VERSION "created by canmatrix"

NS_ :

BS_:

BU_: User ADM_PC_LL25 ADM_PC_BC25 ADM_PC_BP25 ADM_PC_BI25

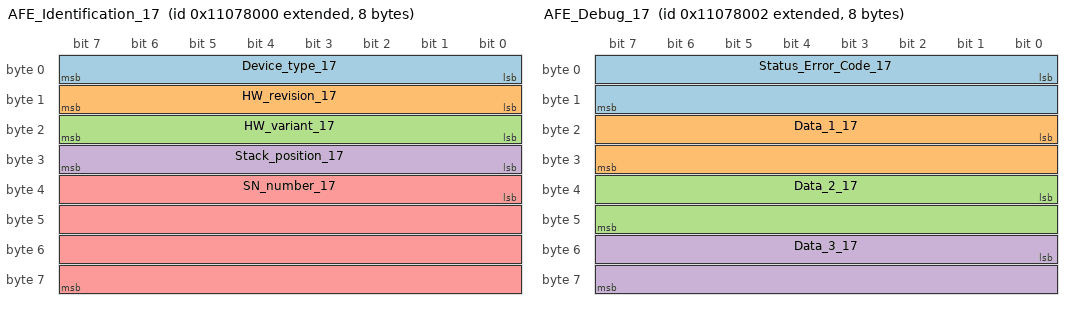
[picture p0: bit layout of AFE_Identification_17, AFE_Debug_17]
BO_ 2433187840 AFE_Identification_17: 8 ADM_PC_BP25
 SG_ Device_type_17 : 0|8@1+ (1,0) [0|255] "" Vector__XXX
 SG_ HW_revision_17 : 8|8@1+ (1,0) [0|255] "" Vector__XXX
 SG_ HW_variant_17 : 16|8@1+ (1,0) [0|255] "" Vector__XXX
 SG_ Stack_position_17 : 24|8@1+ (1,0) [0|255] "" Vector__XXX
 SG_ SN_number_17 : 32|32@1+ (1,0) [0|4294967295] "" Vector__XXX

BO_ 2433187841 AFE_FwInfo_17: 8 ADM_PC_BP25
 SG_ FW_info_mux_17 M : 56|8@1+ (1,0) [0|255] "" Vector__XXX
 SG_ FW_revision_0_17 m0 : 0|8@1+ (1,0) [0|255] "" Vector__XXX
 SG_ FW_revision_1_17 m0 : 8|8@1+ (1,0) [0|255] "" Vector__XXX
 SG_ FW_revision_2_17 m0 : 16|8@1+ (1,0) [0|255] "" Vector__XXX
 SG_ FW_revision_3_17 m0 : 24|8@1+ (1,0) [0|255] "" Vector__XXX
 SG_ FW_revision_4_17 m0 : 32|8@1+ (1,0) [0|255] "" Vector__XXX
 SG_ FW_revision_5_17 m0 : 40|8@1+ (1,0) [0|255] "" Vector__XXX
 SG_ FW_revision_6_17 m0 : 48|8@1+ (1,0) [0|255] "" Vector__XXX
 SG_ FW_revision_7_17 m1 : 0|8@1+ (1,0) [0|255] "" Vector__XXX
 SG_ FW_revision_8_17 m1 : 8|8@1+ (1,0) [0|255] "" Vector__XXX
 SG_ FW_revision_9_17 m1 : 16|8@1+ (1,0) [0|255] "" Vector__XXX
 SG_ FW_revision_10_17 m1 : 24|8@1+ (1,0) [0|255] "" Vector__XXX
 SG_ FW_revision_11_17 m1 : 32|8@1+ (1,0) [0|255] "" Vector__XXX
 SG_ FW_revision_12_17 m1 : 40|8@1+ (1,0) [0|255] "" Vector__XXX
 SG_ FW_revision_13_17 m1 : 48|8@1+ (1,0) [0|255] "" Vector__XXX
 SG_ FW_datecode_0_17 m2 : 0|8@1+ (1,0) [0|255] "" Vector__XXX
 SG_ FW_datecode_1_17 m2 : 8|8@1+ (1,0) [0|255] "" Vector__XXX
 SG_ FW_datecode_2_17 m2 : 16|8@1+ (1,0) [0|255] "" Vector__XXX
 SG_ FW_datecode_3_17 m2 : 24|8@1+ (1,0) [0|255] "" Vector__XXX
 SG_ FW_datecode_4_17 m2 : 32|8@1+ (1,0) [0|255] "" Vector__XXX
 SG_ FW_datecode_5_17 m2 : 40|8@1+ (1,0) [0|255] "" Vector__XXX
 SG_ FW_datecode_6_17 m2 : 48|8@1+ (1,0) [0|255] "" Vector__XXX
 SG_ FW_datecode_7_17 m3 : 0|8@1+ (1,0) [0|255] "" Vector__XXX
 SG_ FW_datecode_8_17 m3 : 8|8@1+ (1,0) [0|255] "" Vector__XXX
 SG_ FW_datecode_9_17 m3 : 16|8@1+ (1,0) [0|255] "" Vector__XXX
 SG_ FW_datecode_10_17 m3 : 24|8@1+ (1,0) [0|255] "" Vector__XXX
 SG_ FW_datecode_11_17 m3 : 32|8@1+ (1,0) [0|255] "" Vector__XXX
 SG_ FW_datecode_12_17 m3 : 40|8@1+ (1,0) [0|255] "" Vector__XXX
 SG_ FW_datecode_13_17 m3 : 48|8@1+ (1,0) [0|255] "" Vector__XXX

BO_ 2433187853 _AFE_Boot_FwInfo_17: 8 ADM_PC_BP25
 SG_ Boot_FW_info_mux_17 M : 56|8@1+ (1,0) [0|255] "" Vector__XXX
 SG_ FW_revision_0_17 m0 : 0|8@1+ (1,0) [0|255] "" Vector__XXX
 SG_ FW_revision_1_17 m0 : 8|8@1+ (1,0) [0|255] "" Vector__XXX
 SG_ FW_revision_2_17 m0 : 16|8@1+ (1,0) [0|255] "" Vector__XXX
 SG_ FW_revision_3_17 m0 : 24|8@1+ (1,0) [0|255] "" Vector__XXX
 SG_ FW_revision_4_17 m0 : 32|8@1+ (1,0) [0|255] "" Vector__XXX
 SG_ FW_revision_5_17 m0 : 40|8@1+ (1,0) [0|255] "" Vector__XXX
 SG_ FW_revision_6_17 m0 : 48|8@1+ (1,0) [0|255] "" Vector__XXX
 SG_ FW_revision_7_17 m1 : 0|8@1+ (1,0) [0|255] "" Vector__XXX
 SG_ FW_revision_8_17 m1 : 8|8@1+ (1,0) [0|255] "" Vector__XXX
 SG_ FW_revision_9_17 m1 : 16|8@1+ (1,0) [0|255] "" Vector__XXX
 SG_ FW_revision_10_17 m1 : 24|8@1+ (1,0) [0|255] "" Vector__XXX
 SG_ FW_revision_11_17 m1 : 32|8@1+ (1,0) [0|255] "" Vector__XXX
 SG_ FW_revision_12_17 m1 : 40|8@1+ (1,0) [0|255] "" Vector__XXX
 SG_ FW_revision_13_17 m1 : 48|8@1+ (1,0) [0|255] "" Vector__XXX
 SG_ FW_datecode_0_17 m2 : 0|8@1+ (1,0) [0|255] "" Vector__XXX
 SG_ FW_datecode_1_17 m2 : 8|8@1+ (1,0) [0|255] "" Vector__XXX
 SG_ FW_datecode_2_17 m2 : 16|8@1+ (1,0) [0|255] "" Vector__XXX
 SG_ FW_datecode_3_17 m2 : 24|8@1+ (1,0) [0|255] "" Vector__XXX
 SG_ FW_datecode_4_17 m2 : 32|8@1+ (1,0) [0|255] "" Vector__XXX
 SG_ FW_datecode_5_17 m2 : 40|8@1+ (1,0) [0|255] "" Vector__XXX
 SG_ FW_datecode_6_17 m2 : 48|8@1+ (1,0) [0|255] "" Vector__XXX
 SG_ FW_datecode_7_17 m3 : 0|8@1+ (1,0) [0|255] "" Vector__XXX
 SG_ FW_datecode_8_17 m3 : 8|8@1+ (1,0) [0|255] "" Vector__XXX
 SG_ FW_datecode_9_17 m3 : 16|8@1+ (1,0) [0|255] "" Vector__XXX
 SG_ FW_datecode_10_17 m3 : 24|8@1+ (1,0) [0|255] "" Vector__XXX
 SG_ FW_datecode_11_17 m3 : 32|8@1+ (1,0) [0|255] "" Vector__XXX
 SG_ FW_datecode_12_17 m3 : 40|8@1+ (1,0) [0|255] "" Vector__XXX
 SG_ FW_datecode_13_17 m3 : 48|8@1+ (1,0) [0|255] "" Vector__XXX

BO_ 2433187842 AFE_Debug_17: 8 ADM_PC_BP25
 SG_ Status_Error_Code_17 : 0|16@1+ (1,0) [0|65535] "" Vector__XXX
 SG_ Data_1_17 : 16|16@1+ (1,0) [0|65535] "" Vector__XXX
 SG_ Data_2_17 : 32|16@1+ (1,0) [0|65535] "" Vector__XXX
 SG_ Data_3_17 : 48|16@1+ (1,0) [0|65535] "" Vector__XXX

BO_ 2433187847 AFE_Status_17: 8 ADM_PC_BP25
 SG_ Running_17 : 0|1@1+ (1,0) [0|1] "" Vector__XXX
 SG_ PWM_17 : 1|1@1+ (1,0) [0|1] "" Vector__XXX
 SG_ Current_dc_loop_mode_17 : 2|1@1+ (1,0) [0|1] "" Vector__XXX
 SG_ Current_ac_loop_mode_17 : 3|1@1+ (1,0) [0|1] "" Vector__XXX
 SG_ Buck_17 : 5|1@1+ (1,0) [0|1] "" Vector__XXX
 SG_ Boost_17 : 6|1@1+ (1,0) [0|1] "" Vector__XXX
 SG_ Precharge_dc_buck_mode_17 : 7|1@1+ (1,0) [0|1] "" Vector__XXX
 SG_ Precharge_dc_boost_mode_17 : 8|1@1+ (1,0) [0|1] "" Vector__XXX
 SG_ Rectifier_3ph_17 : 9|1@1+ (1,0) [0|1] "" Vector__XXX
 SG_ Stack_mode_17 : 10|1@1+ (1,0) [0|1] "" Vector__XXX
 SG_ Master_17 : 11|1@1+ (1,0) [0|1] "" Vector__XXX
 SG_ Slave_17 : 12|1@1+ (1,0) [0|1] "" Vector__XXX
 SG_ Inverter_1ph_17 : 13|1@1+ (1,0) [0|1] "" Vector__XXX
 SG_ Boost_Neutral_17 : 14|1@1+ (1,0) [0|1] "" Vector__XXX
 SG_ Rectifier_1ph_17 : 15|1@1+ (1,0) [0|1] "" Vector__XXX
 SG_ Inverter_3ph_17 : 16|1@1+ (1,0) [0|1] "" Vector__XXX
 SG_ Ready_17 : 17|1@1+ (1,0) [0|1] "" Vector__XXX
 SG_ Inverter_1ph_Sync_17 : 18|1@1+ (1,0) [0|1] "" Vector__XXX
 SG_ Neutral_17 : 19|1@1+ (1,0) [0|1] "" Vector__XXX
 SG_ Rectifier_1ph_Buck_17 : 20|1@1+ (1,0) [0|1] "" Vector__XXX
 SG_ Inverter_1ph_Boost_17 : 21|1@1+ (1,0) [0|1] "" Vector__XXX
 SG_ Rectifier_distributed_17 : 22|1@1+ (1,0) [0|1] "" Vector__XXX
 SG_ MPPT_buck_17 : 23|1@1+ (1,0) [0|1] "" Vector__XXX
 SG_ MPPT_boost_17 : 24|1@1+ (1,0) [0|1] "" Vector__XXX
 SG_ Buck_2p_float_17 : 25|1@1+ (1,0) [0|1] "" Vector__XXX
 SG_ Inverter_1ph_Distributed_17 : 26|1@1+ (1,0) [0|1] "" Vector__XXX

BO_ 2433187846 AFE_Faults_17: 3 ADM_PC_BP25
 SG_ Protection_trip_internal_17 : 0|1@1+ (1,0) [0|1] "" Vector__XXX
 SG_ Protection_trip_external_17 : 1|1@1+ (1,0) [0|1] "" Vector__XXX
 SG_ Phase_U_overcurrent_17 : 2|1@1+ (1,0) [0|1] "" Vector__XXX
 SG_ Phase_U_overvoltage_17 : 3|1@1+ (1,0) [0|1] "" Vector__XXX
 SG_ Phase_U_undervoltage_17 : 4|1@1+ (1,0) [0|1] "" Vector__XXX
 SG_ Phase_V_overvoltage_17 : 5|1@1+ (1,0) [0|1] "" Vector__XXX
 SG_ Phase_V_undervoltage_17 : 6|1@1+ (1,0) [0|1] "" Vector__XXX
 SG_ Phase_V_overcurrent_17 : 7|1@1+ (1,0) [0|1] "" Vector__XXX
 SG_ Phase_W_overvoltage_17 : 8|1@1+ (1,0) [0|1] "" Vector__XXX
 SG_ Phase_W_undervoltage_17 : 9|1@1+ (1,0) [0|1] "" Vector__XXX
 SG_ Phase_W_overcurrent_17 : 10|1@1+ (1,0) [0|1] "" Vector__XXX
 SG_ DC_undervoltage_17 : 11|1@1+ (1,0) [0|1] "" Vector__XXX
 SG_ DC_overvoltage_17 : 12|1@1+ (1,0) [0|1] "" Vector__XXX
 SG_ MOSFET_overtemperature_17 : 13|1@1+ (1,0) [0|1] "" Vector__XXX
 SG_ Inductor_overtemperature_17 : 14|1@1+ (1,0) [0|1] "" Vector__XXX
 SG_ Keep_Alive_not_served_17 : 15|1@1+ (1,0) [0|1] "" Vector__XXX
 SG_ PLL_not_locked_17 : 16|1@1+ (1,0) [0|1] "" Vector__XXX
 SG_ NFO_17 : 20|1@1+ (1,0) [0|1] "" Vector__XXX
 SG_ Measurement_system_failure_17 : 21|1@1+ (1,0) [0|1] "" Vector__XXX
 SG_ EEPROM_failure_17 : 22|1@1+ (1,0) [0|1] "" Vector__XXX
 SG_ System_17 : 23|1@1+ (1,0) [0|1] "" Vector__XXX

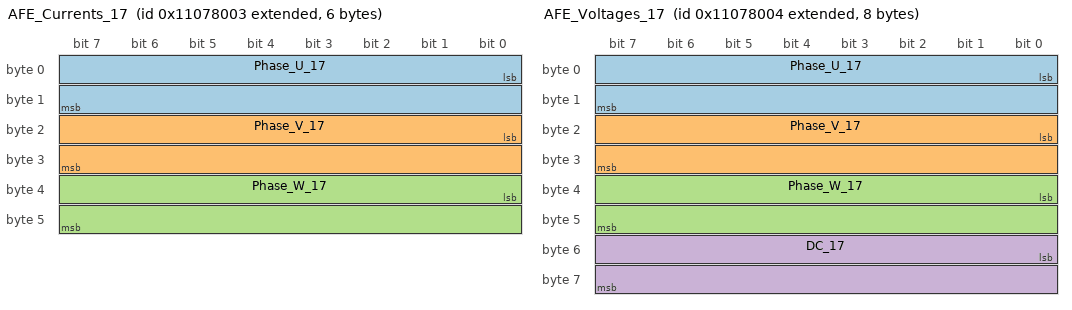
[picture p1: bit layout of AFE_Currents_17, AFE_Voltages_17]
BO_ 2433187843 AFE_Currents_17: 6 ADM_PC_BP25
 SG_ Phase_U_17 : 0|16@1- (0.01,0) [-327.68|327.67] "A" Vector__XXX
 SG_ Phase_V_17 : 16|16@1- (0.01,0) [-327.68|327.67] "A" Vector__XXX
 SG_ Phase_W_17 : 32|16@1- (0.01,0) [-327.68|327.67] "A" Vector__XXX

BO_ 2433187856 AFE_DC_Bus_current_17: 2 ADM_PC_BP25
 SG_ Bus_current_17 : 0|16@1- (0.01,0) [-327.68|327.67] "A" Vector__XXX

BO_ 2433187854 _AFE_Broadcast_17: 8 ADM_PC_BP25
 SG_ Diagnostics_Index_17 M : 56|8@1+ (1,0) [0|255] "" Vector__XXX
 SG_ Phase_U_17 m1 : 8|16@1- (0.01,0) [-327.68|327.67] "A" ADM_PC_BP25
 SG_ Phase_V_17 m1 : 24|16@1- (0.01,0) [-327.68|327.67] "A" ADM_PC_BP25
 SG_ Phase_W_17 m1 : 40|16@1- (0.01,0) [-327.68|327.67] "A" ADM_PC_BP25
 SG_ Stack_position_17 : 0|5@1+ (1,0) [0|31] "" ADM_PC_BP25
 SG_ Group_ID_17 : 5|3@1+ (1,0) [0|7] "" ADM_PC_BP25

BO_ 2433187844 AFE_Voltages_17: 8 ADM_PC_BP25
 SG_ Phase_U_17 : 0|16@1- (0.1,0) [-3276.8|3276.7] "V" Vector__XXX
 SG_ Phase_V_17 : 16|16@1- (0.1,0) [-3276.8|3276.7] "V" Vector__XXX
 SG_ Phase_W_17 : 32|16@1- (0.1,0) [-3276.8|3276.7] "V" Vector__XXX
 SG_ DC_17 : 48|16@1- (0.1,0) [-3276.8|3276.7] "V" Vector__XXX

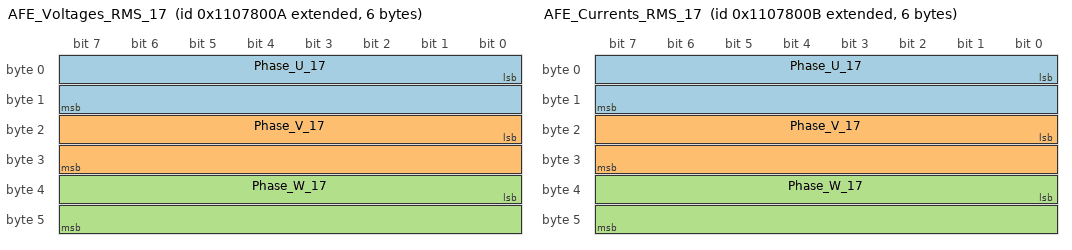
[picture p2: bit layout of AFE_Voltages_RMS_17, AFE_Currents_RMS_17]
BO_ 2433187850 AFE_Voltages_RMS_17: 6 ADM_PC_BP25
 SG_ Phase_U_17 : 0|16@1+ (0.1,0) [0|6553.5] "V" Vector__XXX
 SG_ Phase_V_17 : 16|16@1+ (0.1,0) [0|6553.5] "V" Vector__XXX
 SG_ Phase_W_17 : 32|16@1+ (0.1,0) [0|6553.5] "V" Vector__XXX

BO_ 2433187851 AFE_Currents_RMS_17: 6 ADM_PC_BP25
 SG_ Phase_U_17 : 0|16@1+ (0.01,0) [0.00|655.35] "A" Vector__XXX
 SG_ Phase_V_17 : 16|16@1+ (0.01,0) [0.00|655.35] "A" Vector__XXX
 SG_ Phase_W_17 : 32|16@1+ (0.01,0) [0.00|655.35] "A" Vector__XXX

BO_ 2433187852 AFE_Mains_17: 4 ADM_PC_BP25
 SG_ Frequency_17 : 0|16@1+ (0.01,0) [0.00|655.35] "Hz" Vector__XXX
 SG_ Phase_17 : 16|16@1- (0.1,0) [-3276.8|3276.7] "Deg." Vector__XXX

BO_ 2433187845 AFE_Temperatures_17: 4 ADM_PC_BP25
 SG_ Temp_Bridge_17 : 0|16@1- (0.01,0) [-327.68|327.67] "°C" Vector__XXX
 SG_ Temp_Inductors_17 : 16|16@1- (0.01,0) [-327.68|327.67] "°C" Vector__XXX

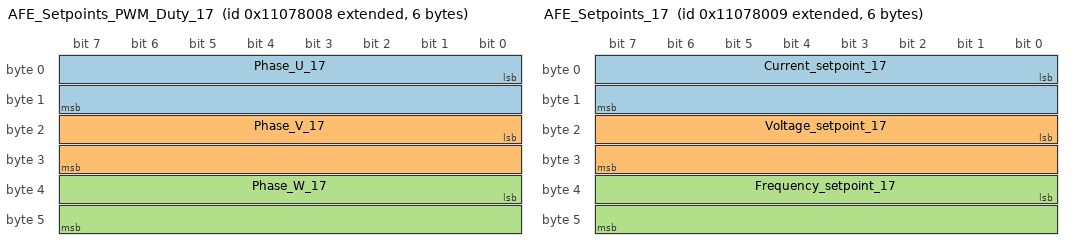
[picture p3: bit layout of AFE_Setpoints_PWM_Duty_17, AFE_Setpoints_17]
BO_ 2433187848 AFE_Setpoints_PWM_Duty_17: 6 ADM_PC_BP25
 SG_ Phase_U_17 : 0|16@1+ (0.001525902,0) [0E-009|99.999987570] "%" Vector__XXX
 SG_ Phase_V_17 : 16|16@1+ (0.001525902,0) [0E-009|99.999987570] "%" Vector__XXX
 SG_ Phase_W_17 : 32|16@1+ (0.001525902,0) [0E-009|99.999987570] "%" Vector__XXX

BO_ 2433187849 AFE_Setpoints_17: 6 ADM_PC_BP25
 SG_ Current_setpoint_17 : 0|16@1- (0.01,0) [-327.68|327.67] "A" Vector__XXX
 SG_ Voltage_setpoint_17 : 16|16@1+ (0.1,0) [0|6553.5] "V" Vector__XXX
 SG_ Frequency_setpoint_17 : 32|16@1+ (0.01,0) [0.00|655.35] "Hz" Vector__XXX

BO_ 2433155168 AFE_Keep_Alive_17: 1 User
 SG_ Keep_Alive_Enable_17 : 0|1@1+ (1,0) [0|1] "" ADM_PC_BP25

BO_ 2433155136 AFE_Mode_Control_17: 8 User
 SG_ Converter_ON_17 : 0|1@1+ (1,0) [0|1] "" ADM_PC_BP25
 SG_ PWM_ON_17 : 1|1@1+ (1,0) [0|1] "" ADM_PC_BP25
 SG_ DC_Current_feedback_ON_17 : 2|1@1+ (1,0) [0|1] "" ADM_PC_BP25
 SG_ AC_Current_feedback_ON_17 : 3|1@1+ (1,0) [0|1] "" ADM_PC_BP25
 SG_ Buck_ON_17 : 5|1@1+ (1,0) [0|1] "" ADM_PC_BP25
 SG_ Boost_ON_17 : 6|1@1+ (1,0) [0|1] "" ADM_PC_BP25
 SG_ Rectifier_3ph_ON_17 : 9|1@1+ (1,0) [0|1] "" ADM_PC_BP25
 SG_ Inverter_1ph_ON_17 : 10|1@1+ (1,0) [0|1] "" ADM_PC_BP25
 SG_ Rectifier_1ph_ON_17 : 11|1@1+ (1,0) [0|1] "" ADM_PC_BP25
 SG_ Boost_Neutral_ON_17 : 12|1@1+ (1,0) [0|1] "" ADM_PC_BP25
 SG_ Inverter_3ph_ON_17 : 13|1@1+ (1,0) [0|1] "" ADM_PC_BP25
 SG_ Inverter_1ph_Sync_ON_17 : 14|1@1+ (1,0) [0|1] "" ADM_PC_BP25
 SG_ Neutral_ON_17 : 15|1@1+ (1,0) [0|1] "" ADM_PC_BP25
 SG_ Rectifier_1ph_Buck_ON_17 : 16|1@1+ (1,0) [0|1] "" ADM_PC_BP25
 SG_ Inverter_1ph_Boost_ON_17 : 17|1@1+ (1,0) [0|1] "" ADM_PC_BP25
 SG_ Rectifier_Distributed_ON_17 : 18|1@1+ (1,0) [0|1] "" ADM_PC_BP25
 SG_ MPPT_buck_ON_17 : 19|1@1+ (1,0) [0|1] "" ADM_PC_BP25
 SG_ MPPT_boost_ON_17 : 20|1@1+ (1,0) [0|1] "" ADM_PC_BP25
 SG_ Buck_2p_float_ON_17 : 21|1@1+ (1,0) [0|1] "" ADM_PC_BP25
 SG_ Inverter_1ph_Distributed_ON_17 : 22|1@1+ (1,0) [0|1] "" ADM_PC_BP25

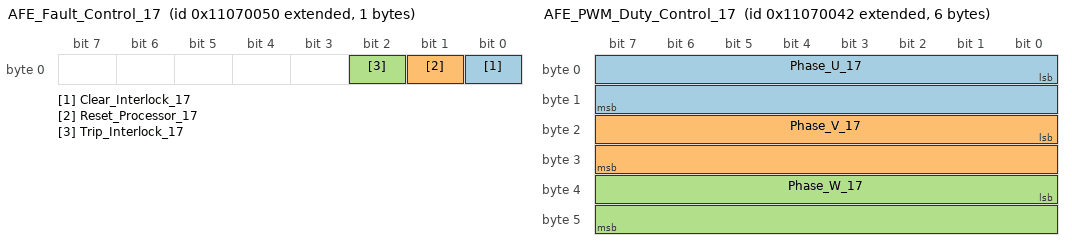
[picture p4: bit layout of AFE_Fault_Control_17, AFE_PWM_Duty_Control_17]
BO_ 2433155152 AFE_Fault_Control_17: 1 User
 SG_ Clear_Interlock_17 : 0|1@1+ (1,0) [0|1] "" ADM_PC_BP25
 SG_ Reset_Processor_17 : 1|1@1+ (1,0) [0|1] "" ADM_PC_BP25
 SG_ Trip_Interlock_17 : 2|1@1+ (1,0) [0|1] "" ADM_PC_BP25

BO_ 2433155137 AFE_Reactive_Current_Setpoint_Co: 2 User
 SG_ Reactive_current_setpoint_17 : 0|16@1- (0.01,0) [-150|150] "A" ADM_PC_BP25

BO_ 2433155138 AFE_PWM_Duty_Control_17: 6 User
 SG_ Phase_U_17 : 0|16@1+ (0.001525902,0) [0E-009|99.999987570] "%" ADM_PC_BP25
 SG_ Phase_V_17 : 16|16@1+ (0.001525902,0) [0E-009|99.999987570] "%" ADM_PC_BP25
 SG_ Phase_W_17 : 32|16@1+ (0.001525902,0) [0E-009|99.999987570] "%" ADM_PC_BP25

BO_ 2433155139 AFE_Current_Setpoint_Control_17: 2 User
 SG_ Current_setpoint_17 : 0|16@1- (0.01,0) [-150|150] "A" ADM_PC_BP25

BO_ 2433155140 AFE_Voltage_Setpoint_Control_17: 2 User
 SG_ Voltage_setpoint_17 : 0|16@1+ (0.1,0) [0|1500] "V" ADM_PC_BP25

BO_ 2433155144 AFE_Frequency_Setpoint_Control_1: 2 User
 SG_ Frequency_setpoint_17 : 0|16@1+ (0.01,0) [40|70] "Hz" ADM_PC_BP25

BO_ 2433155145 AFE_Phase_Setpoint_Control_17: 2 User
 SG_ Phase_setpoint_17 : 0|16@1+ (1,0) [0|360] "deg" ADM_PC_BP25

BO_ 2433155184 AFE_Rectifier_Setpoint_Control_1: 8 User
 SG_ Voltage_setpoint_2_17 : 0|16@1+ (0.1,0) [0|1500] "V" ADM_PC_BP25
 SG_ Current_setpoint_2_17 : 16|16@1- (0.01,0) [-150|150] "A" ADM_PC_BP25

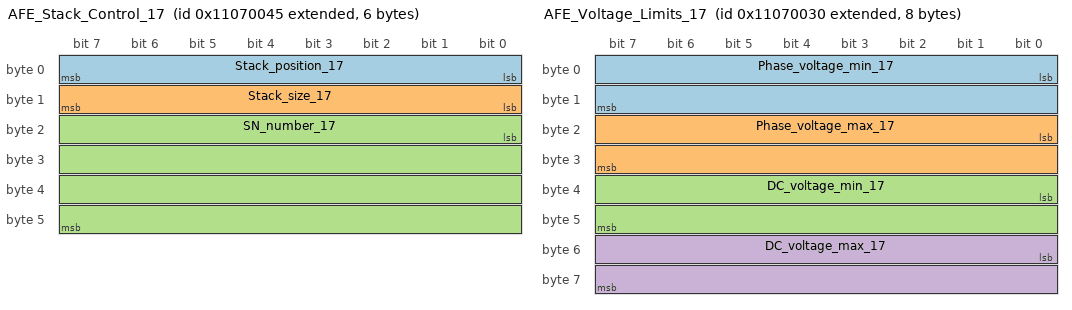
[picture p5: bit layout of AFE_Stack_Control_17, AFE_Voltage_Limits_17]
BO_ 2433155141 AFE_Stack_Control_17: 6 User
 SG_ Stack_position_17 : 0|8@1+ (1,0) [0|255] "" ADM_PC_BP25
 SG_ Stack_size_17 : 8|8@1+ (1,0) [0|255] "" ADM_PC_BP25
 SG_ SN_number_17 : 16|32@1+ (1,0) [0|4294967295] "" ADM_PC_BP25

BO_ 2433155120 AFE_Voltage_Limits_17: 8 User
 SG_ Phase_voltage_min_17 : 0|16@1- (0.1,0) [0|3276.7] "V" ADM_PC_BP25
 SG_ Phase_voltage_max_17 : 16|16@1- (0.1,0) [-3276.8|850] "V" ADM_PC_BP25
 SG_ DC_voltage_min_17 : 32|16@1- (0.1,0) [0|3276.7] "V" ADM_PC_BP25
 SG_ DC_voltage_max_17 : 48|16@1- (0.1,0) [-3276.8|850] "V" ADM_PC_BP25

BO_ 2433155121 AFE_Current_Limits_17: 4 User
 SG_ Phase_current_min_17 : 0|16@1- (0.01,0) [-60|60] "A" ADM_PC_BP25
 SG_ Phase_current_max_17 : 16|16@1- (0.01,0) [-60|60] "A" ADM_PC_BP25

BO_ 2433155148 AFE_Group_Control_17: 1 User
 SG_ Group_ID_17 : 0|8@1+ (1,0) [0|255] "" ADM_PC_BP25

BO_ 2433187855 AFE_Group_Info_17: 1 ADM_PC_BP25
 SG_ Group_ID_17 : 0|8@1+ (1,0) [0|255] "" Vector__XXX

BO_ 2433155169 AFE_System_Flags_Control_17: 8 User
 SG_ Factory_mode_17 : 0|1@1+ (1,0) [0|1] "" ADM_PC_BP25
 SG_ Silent_CAN_mode_17 : 1|1@1+ (1,0) [0|1] "" ADM_PC_BP25

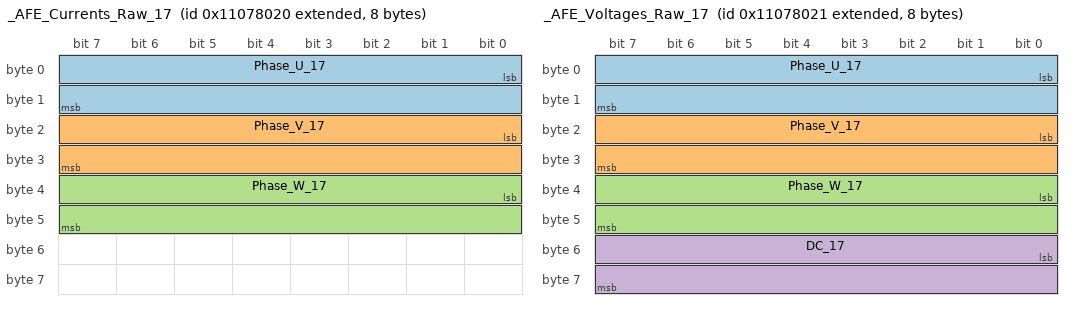
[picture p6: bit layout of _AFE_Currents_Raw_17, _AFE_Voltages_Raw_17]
BO_ 2433187872 _AFE_Currents_Raw_17: 8 ADM_PC_BP25
 SG_ Phase_U_17 : 0|16@1- (1,0) [-32768|32767] "" Vector__XXX
 SG_ Phase_V_17 : 16|16@1- (1,0) [-32768|32767] "" Vector__XXX
 SG_ Phase_W_17 : 32|16@1- (1,0) [-32768|32767] "" Vector__XXX

BO_ 2433187873 _AFE_Voltages_Raw_17: 8 ADM_PC_BP25
 SG_ Phase_U_17 : 0|16@1- (1,0) [-32768|32767] "" Vector__XXX
 SG_ Phase_V_17 : 16|16@1- (1,0) [-32768|32767] "" Vector__XXX
 SG_ Phase_W_17 : 32|16@1- (1,0) [-32768|32767] "" Vector__XXX
 SG_ DC_17 : 48|16@1- (1,0) [-32768|32767] "" Vector__XXX

BO_ 2433155146 _AFE_ADC_Calibration_Mode_17: 1 User
 SG_ Calibration_Index_17 M : 2|5@1+ (1,0) [0|31] "" Vector__XXX
 SG_ Current_U_17 m1 : 0|2@1+ (1,0) [0|3] "" ADM_PC_BP25
 SG_ Current_V_17 m2 : 0|2@1+ (1,0) [0|3] "" ADM_PC_BP25
 SG_ Current_W_17 m3 : 0|2@1+ (1,0) [0|3] "" ADM_PC_BP25
 SG_ Voltage_U_17 m4 : 0|2@1+ (1,0) [0|3] "" ADM_PC_BP25
 SG_ Voltage_V_17 m5 : 0|2@1+ (1,0) [0|3] "" ADM_PC_BP25
 SG_ Voltage_W_17 m6 : 0|2@1+ (1,0) [0|3] "" ADM_PC_BP25
 SG_ Voltage_DC_17 m7 : 0|2@1+ (1,0) [0|3] "" ADM_PC_BP25
 SG_ start_17 : 7|1@1+ (1,0) [0|1] "" ADM_PC_BP25

BO_ 2433155147 _AFE_ADC_Calibration_Setpoint_17: 3 User
 SG_ Calibration_Index_17 M : 16|5@1+ (1,0) [0|31] "" Vector__XXX
 SG_ Current_U_17 m1 : 0|16@1- (0.01,0) [-100|100] "A" ADM_PC_BP25
 SG_ Current_V_17 m2 : 0|16@1- (0.01,0) [-100|100] "A" ADM_PC_BP25
 SG_ Current_W_17 m3 : 0|16@1- (0.01,0) [-100|100] "A" ADM_PC_BP25
 SG_ Voltage_U_17 m4 : 0|16@1+ (0.1,0) [0|1500] "V" ADM_PC_BP25
 SG_ Voltage_V_17 m5 : 0|16@1+ (0.1,0) [0|1500] "V" ADM_PC_BP25
 SG_ Voltage_W_17 m6 : 0|16@1+ (0.1,0) [0|1500] "V" ADM_PC_BP25
 SG_ Voltage_DC_17 m7 : 0|16@1+ (0.1,0) [0|1500] "V" ADM_PC_BP25
 SG_ point_17 : 21|3@1+ (1,0) [0|7] "" ADM_PC_BP25

BO_ 2433155142 _AFE_Calibration_Offset_Update_1: 6 User
 SG_ Calibration_Index_17 M : 16|16@1+ (1,0) [0|65535] "" Vector__XXX
 SG_ Current_U_17 m0 : 0|16@1- (1,0) [-32768|32767] "ADC Counts" ADM_PC_BP25
 SG_ Current_V_17 m1 : 0|16@1- (1,0) [-32768|32767] "ADC Counts" ADM_PC_BP25
 SG_ Current_W_17 m2 : 0|16@1- (1,0) [-32768|32767] "ADC Counts" ADM_PC_BP25
 SG_ Voltage_U_17 m3 : 0|16@1- (1,0) [-32768|32767] "ADC Counts" ADM_PC_BP25
 SG_ Voltage_V_17 m4 : 0|16@1- (1,0) [-32768|32767] "ADC Counts" ADM_PC_BP25
 SG_ Voltage_W_17 m5 : 0|16@1- (1,0) [-32768|32767] "ADC Counts" ADM_PC_BP25
 SG_ Voltage_DC_17 m6 : 0|16@1- (1,0) [-32768|32767] "ADC Counts" ADM_PC_BP25
 SG_ CRC_17 : 32|16@1+ (1,0) [0|65535] "-" ADM_PC_BP25

BO_ 2433155143 _AFE_Calibration_Scale_Update_17: 6 User
 SG_ Calibration_Index_17 M : 16|16@1+ (1,0) [0|65535] "" Vector__XXX
 SG_ Current_U_17 m0 : 0|16@1- (0.0000152587890625,0) [-0.5000000000000000|0.4999847412109375] "scale = 1.0 + value" ADM_PC_BP25
 SG_ Current_V_17 m1 : 0|16@1- (0.0000152587890625,0) [-0.5000000000000000|0.4999847412109375] "scale = 1.0 + value" ADM_PC_BP25
 SG_ Current_W_17 m2 : 0|16@1- (0.0000152587890625,0) [-0.5000000000000000|0.4999847412109375] "scale = 1.0 + value" ADM_PC_BP25
 SG_ Voltage_U_17 m3 : 0|16@1- (0.0000152587890625,0) [-0.5000000000000000|0.4999847412109375] "scale = 1.0 + value" ADM_PC_BP25
 SG_ Voltage_V_17 m4 : 0|16@1- (0.0000152587890625,0) [-0.5000000000000000|0.4999847412109375] "scale = 1.0 + value" ADM_PC_BP25
 SG_ Voltage_W_17 m5 : 0|16@1- (0.0000152587890625,0) [-0.5000000000000000|0.4999847412109375] "scale = 1.0 + value" ADM_PC_BP25
 SG_ Voltage_DC_17 m6 : 0|16@1- (0.0000152587890625,0) [-0.5000000000000000|0.4999847412109375] "scale = 1.0 + value" ADM_PC_BP25
 SG_ CRC_17 : 32|16@1+ (1,0) [0|65535] "-" ADM_PC_BP25

BO_ 2433187921 _AFE_Calibration_Adc_Scale_17: 6 ADM_PC_BP25
 SG_ Adc_Index_17 M : 32|16@1+ (1,0) [0|65535] "" Vector__XXX
 SG_ Current_U_17 m0 : 0|32@1+ (1,0) [0|4294967295] "1 / adc_bins" User
 SG_ Current_V_17 m1 : 0|32@1+ (1,0) [0|4294967295] "1 / adc_bins" User
 SG_ Current_W_17 m2 : 0|32@1+ (1,0) [0|4294967295] "1 / adc_bins" User
 SG_ Voltage_U_17 m3 : 0|32@1+ (1,0) [0|4294967295] "1 / adc_bins" User
 SG_ Voltage_V_17 m4 : 0|32@1+ (1,0) [0|4294967295] "1 / adc_bins" User
 SG_ Voltage_W_17 m5 : 0|32@1+ (1,0) [0|4294967295] "1 / adc_bins" User
 SG_ Voltage_DC_17 m6 : 0|32@1+ (1,0) [0|4294967295] "1 / adc_bins" User

BO_ 2433187922 _AFE_Calibration_Adc_Fs_17: 6 ADM_PC_BP25
 SG_ Adc_Index_17 M : 32|16@1+ (1,0) [0|65535] "" Vector__XXX
 SG_ Current_U_17 m0 : 0|32@1+ (1,0) [0|4294967295] "Fullscale" User
 SG_ Current_V_17 m1 : 0|32@1+ (1,0) [0|4294967295] "Fullscale" User
 SG_ Current_W_17 m2 : 0|32@1+ (1,0) [0|4294967295] "Fullscale" User
 SG_ Voltage_U_17 m3 : 0|32@1+ (1,0) [0|4294967295] "Fullscale" User
 SG_ Voltage_V_17 m4 : 0|32@1+ (1,0) [0|4294967295] "Fullscale" User
 SG_ Voltage_W_17 m5 : 0|32@1+ (1,0) [0|4294967295] "Fullscale" User
 SG_ Voltage_DC_17 m6 : 0|32@1+ (1,0) [0|4294967295] "Fullscale" User

BO_ 2433187923 _AFE_Calibration_Adc_Offset_17: 4 ADM_PC_BP25
 SG_ Adc_Index_17 M : 16|16@1+ (1,0) [0|65535] "" Vector__XXX
 SG_ Current_U_17 m0 : 0|16@1- (1,0) [-32768|32767] "-" User
 SG_ Current_V_17 m1 : 0|16@1- (1,0) [-32768|32767] "-" User
 SG_ Current_W_17 m2 : 0|16@1- (1,0) [-32768|32767] "-" User
 SG_ Voltage_U_17 m3 : 0|16@1- (1,0) [-32768|32767] "-" User
 SG_ Voltage_V_17 m4 : 0|16@1- (1,0) [-32768|32767] "-" User
 SG_ Voltage_W_17 m5 : 0|16@1- (1,0) [-32768|32767] "-" User
 SG_ Voltage_DC_17 m6 : 0|16@1- (1,0) [-32768|32767] "-" User

BO_ 2433187924 _AFE_Calibration_Adc_Gain_17: 4 ADM_PC_BP25
 SG_ Adc_Index_17 M : 16|16@1+ (1,0) [0|65535] "" Vector__XXX
 SG_ Current_U_17 m0 : 0|16@1- (1,0) [-32768|32767] "-" User
 SG_ Current_V_17 m1 : 0|16@1- (1,0) [-32768|32767] "-" User
 SG_ Current_W_17 m2 : 0|16@1- (1,0) [-32768|32767] "-" User
 SG_ Voltage_U_17 m3 : 0|16@1- (1,0) [-32768|32767] "-" User
 SG_ Voltage_V_17 m4 : 0|16@1- (1,0) [-32768|32767] "-" User
 SG_ Voltage_W_17 m5 : 0|16@1- (1,0) [-32768|32767] "-" User
 SG_ Voltage_DC_17 m6 : 0|16@1- (1,0) [-32768|32767] "-" User

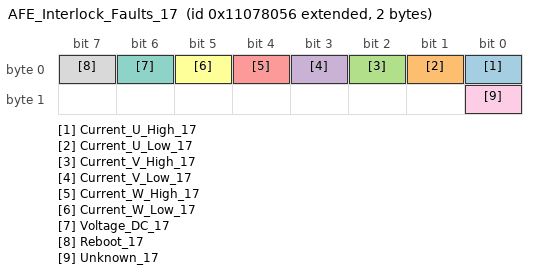
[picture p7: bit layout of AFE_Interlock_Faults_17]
BO_ 2433187926 AFE_Interlock_Faults_17: 2 ADM_PC_BP25
 SG_ Current_U_High_17 : 0|1@1+ (1,0) [0|1] "" Vector__XXX
 SG_ Current_U_Low_17 : 1|1@1+ (1,0) [0|1] "" Vector__XXX
 SG_ Current_V_High_17 : 2|1@1+ (1,0) [0|1] "" Vector__XXX
 SG_ Current_V_Low_17 : 3|1@1+ (1,0) [0|1] "" Vector__XXX
 SG_ Current_W_High_17 : 4|1@1+ (1,0) [0|1] "" Vector__XXX
 SG_ Current_W_Low_17 : 5|1@1+ (1,0) [0|1] "" Vector__XXX
 SG_ Voltage_DC_17 : 6|1@1+ (1,0) [0|1] "" Vector__XXX
 SG_ Reboot_17 : 7|1@1+ (1,0) [0|1] "" Vector__XXX
 SG_ Unknown_17 : 8|1@1+ (1,0) [0|1] "" Vector__XXX

BO_TX_BU_ 2433155136 : User,ADM_PC_LL25,ADM_PC_BC25,ADM_PC_BI25;
BO_TX_BU_ 2433155139 : User,ADM_PC_LL25,ADM_PC_BC25,ADM_PC_BI25;
BO_TX_BU_ 2433155140 : User,ADM_PC_LL25,ADM_PC_BC25,ADM_PC_BI25;
CM_ BO_ 2433187840  "Identification of the device";
CM_ BO_ 2433187841  "Git revision of the DSP firmware";
CM_ BO_ 2433187853  "Git revision of the bootloader firmware.";
CM_ BO_ 2433187842  "Values for debugging of HW/SW problems";
CM_ BO_ 2433187847  "Status bitfield";
CM_ BO_ 2433187846  "Fault bitfield";
CM_ BO_ 2433187843  "Current of phases U, V, W";
CM_ BO_ 2433187856  "Current of of the DC Bus";
CM_ BO_ 2433187854  "All AFEs will listen to this message";
CM_ BO_ 2433187851  "RMS Current of phases U, V, W";
CM_ BO_ 2433187852  "Three-Phase mains health (frequency, phase...)";
CM_ BO_ 2433187845  "Readouts of the module temperature sensors";
CM_ BO_ 2433187848  "Setpoints";
CM_ BO_ 2433187849  "Setpoints";
CM_ BO_ 2433155168  "Keep alive ping message. ";
CM_ BO_ 2433155136  "Operation Mode control: sets the converter operation mode";
CM_ BO_ 2433155152  "Fault Control: actions to clear faults and reset the system";
CM_ BO_ 2433155137  "Reactive power setpoint control.";
CM_ BO_ 2433155138  "PWM duty cycle control";
CM_ BO_ 2433155139  "Current setpoint control";
CM_ BO_ 2433155140  "Voltage setpoint control";
CM_ BO_ 2433155144  "Frequency setpoint control";
CM_ BO_ 2433155145  "Phase setpoint control";
CM_ BO_ 2433155184  "Additional voltage and current setpoints in single-phase rectifier and inverter control modes.";
CM_ BO_ 2433155141  "PFC stack control";
CM_ BO_ 2433155120  "Set the input and output voltage limits (minimum and maximum)";
CM_ BO_ 2433155121  "Set the output current limits (mminimum and maximum)";
CM_ BO_ 2433155148  "Set the Group ID of the device";
CM_ BO_ 2433187855  "Contains the Group ID of the device";
CM_ BO_ 2433155169  "Control the system flags";
CM_ BO_ 2433187872  "Current of phases A and B";
CM_ BO_ 2433187873  "Current of phases A and B";
CM_ BO_ 2433155146  "Automatic ADC calibration.";
CM_ BO_ 2433155147  "Setpoint for automatic ADC calibration.";
CM_ BO_ 2433155142  "Update of the calibration table for offsets.";
CM_ BO_ 2433155143  "Update of the calibration table for scales.";
CM_ BO_ 2433187921  "
                Adc scale (resolution) value of readouts.
            ";
CM_ BO_ 2433187922  "
                Adc fullscale value of readouts.
            ";
CM_ BO_ 2433187923  "
                Readout of ADC calibration data (offset) from EEPROM.
            ";
CM_ BO_ 2433187924  "
                Readout of ADC calibration data (gain) from EEPROM.
            ";
CM_ BO_ 2433187926  "Fault bitfield";

CM_ SG_ 2433187840 Device_type_17 "The device identification field, uniquely identifies the sender in the network";
CM_ SG_ 2433187840 HW_revision_17 "The hardware revision number";
CM_ SG_ 2433187840 HW_variant_17 "The DSP firmware revision number";
CM_ SG_ 2433187840 Stack_position_17 "Position of the module within the stack";
CM_ SG_ 2433187840 SN_number_17 "Unique module serial number";
CM_ SG_ 2433187841 FW_revision_0_17 "Character 0";
CM_ SG_ 2433187841 FW_revision_1_17 "Character 1";
CM_ SG_ 2433187841 FW_revision_2_17 "Character 2";
CM_ SG_ 2433187841 FW_revision_3_17 "Character 3";
CM_ SG_ 2433187841 FW_revision_4_17 "Character 3";
CM_ SG_ 2433187841 FW_revision_5_17 "Character 3";
CM_ SG_ 2433187841 FW_revision_6_17 "Character 3";
CM_ SG_ 2433187841 FW_revision_7_17 "Character 7";
CM_ SG_ 2433187841 FW_revision_8_17 "Character 8";
CM_ SG_ 2433187841 FW_revision_9_17 "Character 9";
CM_ SG_ 2433187841 FW_revision_10_17 "Character 10";
CM_ SG_ 2433187841 FW_revision_11_17 "Character 11";
CM_ SG_ 2433187841 FW_revision_12_17 "Character 12";
CM_ SG_ 2433187841 FW_revision_13_17 "Character 13";
CM_ SG_ 2433187841 FW_datecode_0_17 "Character 0";
CM_ SG_ 2433187841 FW_datecode_1_17 "Character 1";
CM_ SG_ 2433187841 FW_datecode_2_17 "Character 2";
CM_ SG_ 2433187841 FW_datecode_3_17 "Character 3";
CM_ SG_ 2433187841 FW_datecode_4_17 "Character 3";
CM_ SG_ 2433187841 FW_datecode_5_17 "Character 3";
CM_ SG_ 2433187841 FW_datecode_6_17 "Character 3";
CM_ SG_ 2433187841 FW_datecode_7_17 "Character 7";
CM_ SG_ 2433187841 FW_datecode_8_17 "Character 8";
CM_ SG_ 2433187841 FW_datecode_9_17 "Character 9";
CM_ SG_ 2433187841 FW_datecode_10_17 "Character 10";
CM_ SG_ 2433187841 FW_datecode_11_17 "Character 11";
CM_ SG_ 2433187841 FW_datecode_12_17 "Character 12";
CM_ SG_ 2433187841 FW_datecode_13_17 "Character 13";
CM_ SG_ 2433187853 FW_revision_0_17 "Character 0";
CM_ SG_ 2433187853 FW_revision_1_17 "Character 1";
CM_ SG_ 2433187853 FW_revision_2_17 "Character 2";
CM_ SG_ 2433187853 FW_revision_3_17 "Character 3";
CM_ SG_ 2433187853 FW_revision_4_17 "Character 3";
CM_ SG_ 2433187853 FW_revision_5_17 "Character 3";
CM_ SG_ 2433187853 FW_revision_6_17 "Character 3";
CM_ SG_ 2433187853 FW_revision_7_17 "Character 7";
CM_ SG_ 2433187853 FW_revision_8_17 "Character 8";
CM_ SG_ 2433187853 FW_revision_9_17 "Character 9";
CM_ SG_ 2433187853 FW_revision_10_17 "Character 10";
CM_ SG_ 2433187853 FW_revision_11_17 "Character 11";
CM_ SG_ 2433187853 FW_revision_12_17 "Character 12";
CM_ SG_ 2433187853 FW_revision_13_17 "Character 13";
CM_ SG_ 2433187853 FW_datecode_0_17 "Character 0";
CM_ SG_ 2433187853 FW_datecode_1_17 "Character 1";
CM_ SG_ 2433187853 FW_datecode_2_17 "Character 2";
CM_ SG_ 2433187853 FW_datecode_3_17 "Character 3";
CM_ SG_ 2433187853 FW_datecode_4_17 "Character 3";
CM_ SG_ 2433187853 FW_datecode_5_17 "Character 3";
CM_ SG_ 2433187853 FW_datecode_6_17 "Character 3";
CM_ SG_ 2433187853 FW_datecode_7_17 "Character 7";
CM_ SG_ 2433187853 FW_datecode_8_17 "Character 8";
CM_ SG_ 2433187853 FW_datecode_9_17 "Character 9";
CM_ SG_ 2433187853 FW_datecode_10_17 "Character 10";
CM_ SG_ 2433187853 FW_datecode_11_17 "Character 11";
CM_ SG_ 2433187853 FW_datecode_12_17 "Character 12";
CM_ SG_ 2433187853 FW_datecode_13_17 "Character 13";
CM_ SG_ 2433187842 Status_Error_Code_17 "Main status / error code as defined in errno/errno.h";
CM_ SG_ 2433187842 Data_1_17 "Additional information for the error/status";
CM_ SG_ 2433187842 Data_2_17 "Additional information for the error/status";
CM_ SG_ 2433187842 Data_3_17 "Additional information for the error/status";
CM_ SG_ 2433187847 Running_17 "Indicates if converter is running.";
CM_ SG_ 2433187847 PWM_17 "Indicates if converter is in PWM control mode.";
CM_ SG_ 2433187847 Current_dc_loop_mode_17 "Indicates if the current DC loop is enabled.";
CM_ SG_ 2433187847 Current_ac_loop_mode_17 "Indicates if the current AC loop is enabled.";
CM_ SG_ 2433187847 Buck_17 "Indicates if converter is in buck control mode.";
CM_ SG_ 2433187847 Boost_17 "Indicates if converter is in boost control mode.";
CM_ SG_ 2433187847 Precharge_dc_buck_mode_17 "Indicates if the precharge DC mode is enabled - buck direction.";
CM_ SG_ 2433187847 Precharge_dc_boost_mode_17 "Indicates if the precharge DC mode is enabled - boost direction.";
CM_ SG_ 2433187847 Rectifier_3ph_17 "Indicates if converter is in three-phase rectifier control mode.";
CM_ SG_ 2433187847 Stack_mode_17 "Indicates if converter is operating in stack mode.";
CM_ SG_ 2433187847 Master_17 "Indicates if converter is master in the stack.";
CM_ SG_ 2433187847 Slave_17 "Indicates if converter is slave in the stack.";
CM_ SG_ 2433187847 Inverter_1ph_17 "Indicates if converter is in single-phase inverter control mode.";
CM_ SG_ 2433187847 Boost_Neutral_17 "Indicates if converter is in boost control mode with neutral generation.";
CM_ SG_ 2433187847 Rectifier_1ph_17 "Indicates if converter is in single-phase rectifier control mode.";
CM_ SG_ 2433187847 Inverter_3ph_17 "Indicates if converter is in three-phase inverter control mode.";
CM_ SG_ 2433187847 Ready_17 "Indicates if converter is ready for operation.";
CM_ SG_ 2433187847 Inverter_1ph_Sync_17 "Single-phase inverter control mode with phase synchronization.";
CM_ SG_ 2433187847 Neutral_17 "Open-loop neutral generation.";
CM_ SG_ 2433187847 Rectifier_1ph_Buck_17 "Single-phase rectifier with buck on one leg.";
CM_ SG_ 2433187847 Inverter_1ph_Boost_17 "Single-phase inverter with boost on one leg.";
CM_ SG_ 2433187847 Rectifier_distributed_17 "Not available at the moment";
CM_ SG_ 2433187847 MPPT_buck_17 "Not available at the moment";
CM_ SG_ 2433187847 MPPT_boost_17 "Not available at the moment";
CM_ SG_ 2433187847 Buck_2p_float_17 "Buck in phases L1 and L2. Phase L3 is left floating (high impedance)";
CM_ SG_ 2433187847 Inverter_1ph_Distributed_17 "Single-phase inverter mode  distributed";
CM_ SG_ 2433187846 Protection_trip_internal_17 "This flagg is asserted if the interlock is open due to an internal fault condition (self-protection)";
CM_ SG_ 2433187846 Protection_trip_external_17 "This flag is asserted if the interlock is open due to an external condition received in the module.";
CM_ SG_ 2433187846 Phase_U_overcurrent_17 "Indicates an overcurrent event on Phase U. The overcurrent event is triggered when the measured phase current is over the programmed current limit.";
CM_ SG_ 2433187846 Phase_U_overvoltage_17 "Indicates an overvoltage event on Phase U. The overvoltage event is triggered when the measured phase voltage is over the programmed voltage limit.";
CM_ SG_ 2433187846 Phase_U_undervoltage_17 "Indicates an undervoltage event on Phase U. The overvoltage event is triggered when the measured phase voltage is over the programmed voltage limit.";
CM_ SG_ 2433187846 Phase_V_overvoltage_17 "Indicates an overvoltage event on Phase V. The overvoltage event is triggered when the measured phase voltage is over the programmed voltage limit.";
CM_ SG_ 2433187846 Phase_V_undervoltage_17 "Indicates an undervoltage event on Phase U. The overvoltage event is triggered when the measured phase voltage is over the programmed voltage limit.";
CM_ SG_ 2433187846 Phase_V_overcurrent_17 "Indicates an overcurrent event on Phase U. The overcurrent event is triggered when the measured phase current is over the programmed current limit.";
CM_ SG_ 2433187846 Phase_W_overvoltage_17 "Indicates an overvoltage event on Phase U. The overvoltage event is triggered when the measured phase voltage is over the programmed voltage limit.";
CM_ SG_ 2433187846 Phase_W_undervoltage_17 "Indicates an undervoltage event on Phase U. The overvoltage event is triggered when the measured phase voltage is over the programmed voltage limit.";
CM_ SG_ 2433187846 Phase_W_overcurrent_17 "Indicates an overcurrent event on Phase U. The overcurrent event is triggered when the measured phase current is over the programmed current limit.";
CM_ SG_ 2433187846 DC_undervoltage_17 "DC bus undervoltage condition. The undervoltage condition is asserted when the measured dc bus voltage is under the programmed voltage limit.";
CM_ SG_ 2433187846 DC_overvoltage_17 "DC bus overvoltage condition. The overvoltage condition is asserted when the measured dc bus voltage is over the programmed voltage limit.";
CM_ SG_ 2433187846 MOSFET_overtemperature_17 "This flag is asserted when the temperature of the MOSFET block is too high.";
CM_ SG_ 2433187846 Inductor_overtemperature_17 "This flag is asserted when the temperature of the inductor block is too high.";
CM_ SG_ 2433187846 Keep_Alive_not_served_17 "The Keep Alive feature is enabled but it was not served with the periodic message.";
CM_ SG_ 2433187846 PLL_not_locked_17 "Flag asserted when in rectifier modes, the PLL went out of lock condition";
CM_ SG_ 2433187846 Measurement_system_failure_17 "The voltages/currents measurement system is malfunctionning, and readouts are not guaranteed to be accurate.";
CM_ SG_ 2433187846 EEPROM_failure_17 "The configuration EEPROM failed to load or save the module configuration.";
CM_ SG_ 2433187843 Phase_U_17 "Phase current is the MOSFET loop current, in the branch U of the converter.";
CM_ SG_ 2433187843 Phase_V_17 "Phase current is the MOSFET loop current, in the branch V of the converter.";
CM_ SG_ 2433187843 Phase_W_17 "Phase current is the MOSFET loop current, in the branch W of the converter.";
CM_ SG_ 2433187856 Bus_current_17 "DC Bus current is possitive when current goes from input to output";
CM_ SG_ 2433187854 Phase_U_17 "Phase current is the MOSFET loop current, in the branch U of the converter.";
CM_ SG_ 2433187854 Phase_V_17 "Phase current is the MOSFET loop current, in the branch V of the converter.";
CM_ SG_ 2433187854 Phase_W_17 "Phase current is the MOSFET loop current, in the branch W of the converter.";
CM_ SG_ 2433187854 Stack_position_17 "Sender Stack position";
CM_ SG_ 2433187854 Group_ID_17 "Sender Group ID";
CM_ SG_ 2433187851 Phase_U_17 "RMS Phase current is the MOSFET loop current, in the branch U of the converter.";
CM_ SG_ 2433187851 Phase_V_17 "RMS Phase current is the MOSFET loop current, in the branch V of the converter.";
CM_ SG_ 2433187851 Phase_W_17 "RMS Phase current is the MOSFET loop current, in the branch W of the converter.";
CM_ SG_ 2433187852 Frequency_17 "Frequency of Three-Phase system";
CM_ SG_ 2433187852 Phase_17 "Phase of Three-Phase system";
CM_ SG_ 2433187845 Temp_Bridge_17 "Temperature of the MOSFET block";
CM_ SG_ 2433187845 Temp_Inductors_17 "Temperature of the inductors";
CM_ SG_ 2433187848 Phase_U_17 "The actual PWM duty cycle setpoint";
CM_ SG_ 2433187848 Phase_V_17 "The actual PWM duty cycle setpoint";
CM_ SG_ 2433187848 Phase_W_17 "The actual PWM duty cycle setpoint";
CM_ SG_ 2433187849 Current_setpoint_17 "The actual current setpoint";
CM_ SG_ 2433187849 Voltage_setpoint_17 "The actual voltage setpoint";
CM_ SG_ 2433187849 Frequency_setpoint_17 "The actual frequency setpoint";
CM_ SG_ 2433155168 Keep_Alive_Enable_17 "If set to 1, module will expect to receive this message every second repeatedly, or it will stop operation";
CM_ SG_ 2433155136 Converter_ON_17 "Enable the converter.";
CM_ SG_ 2433155136 PWM_ON_17 "Enable the PWM control mode.";
CM_ SG_ 2433155136 DC_Current_feedback_ON_17 "Enable the DC current loop";
CM_ SG_ 2433155136 AC_Current_feedback_ON_17 "Enable the AC current loop";
CM_ SG_ 2433155136 Buck_ON_17 "Enable the buck control mode.";
CM_ SG_ 2433155136 Boost_ON_17 "Enable the boost control mode.";
CM_ SG_ 2433155136 Rectifier_3ph_ON_17 "Enable the three-phase rectifier control mode.";
CM_ SG_ 2433155136 Inverter_1ph_ON_17 "Enable the single-phase inverter control mode.";
CM_ SG_ 2433155136 Rectifier_1ph_ON_17 "Enable the single-phase rectifier control mode.";
CM_ SG_ 2433155136 Boost_Neutral_ON_17 "Enable the boost control mode with neutral generation.";
CM_ SG_ 2433155136 Inverter_3ph_ON_17 "Enable the three-phase inverter control mode.";
CM_ SG_ 2433155136 Inverter_1ph_Sync_ON_17 "Single-phase inverter control mode with phase synchronization.";
CM_ SG_ 2433155136 Neutral_ON_17 "Open-loop neutral generation.";
CM_ SG_ 2433155136 Rectifier_1ph_Buck_ON_17 "Single-phase rectifier with buck on one leg.";
CM_ SG_ 2433155136 Inverter_1ph_Boost_ON_17 "Single-phase inverter with boost on one leg.";
CM_ SG_ 2433155136 Rectifier_Distributed_ON_17 "Single-phase (floating) distributed rectifier";
CM_ SG_ 2433155136 MPPT_buck_ON_17 "MPPT buck";
CM_ SG_ 2433155136 MPPT_boost_ON_17 "MPPT boost";
CM_ SG_ 2433155136 Buck_2p_float_ON_17 "Boost on L1 and L2. Floating L3 (high-impedance)";
CM_ SG_ 2433155136 Inverter_1ph_Distributed_ON_17 "Single-phase inverter mode distributed";
CM_ SG_ 2433155152 Clear_Interlock_17 "Clears the converter interlock";
CM_ SG_ 2433155152 Reset_Processor_17 "Reset the converter DSP";
CM_ SG_ 2433155152 Trip_Interlock_17 "Trip the inetrnal Interlock";
CM_ SG_ 2433155137 Reactive_current_setpoint_17 "This defines reactive current setpoint for 3-phase rectifier mode";
CM_ SG_ 2433155138 Phase_U_17 "The actual PWM duty cycle setpoint";
CM_ SG_ 2433155138 Phase_V_17 "The actual PWM duty cycle setpoint";
CM_ SG_ 2433155138 Phase_W_17 "The actual PWM duty cycle setpoint";
CM_ SG_ 2433155139 Current_setpoint_17 "Sets the output current setpoint. Active only when the current loop is enabled";
CM_ SG_ 2433155140 Voltage_setpoint_17 "Sets the output voltage setpoint. Active only when the voltage loop is enabled";
CM_ SG_ 2433155144 Frequency_setpoint_17 "Sets the frequency for single-phase and three-phase generator modes.";
CM_ SG_ 2433155145 Phase_setpoint_17 "Sets the phase for inverter control modes.";
CM_ SG_ 2433155141 Stack_position_17 "The converter position within the stack";
CM_ SG_ 2433155141 Stack_size_17 "How many PFC converters are in stack in total";
CM_ SG_ 2433155141 SN_number_17 "Unique module serial number";
CM_ SG_ 2433155120 Phase_voltage_min_17 "Minimum tolerated phase voltage";
CM_ SG_ 2433155120 Phase_voltage_max_17 "Maximum allowable phase voltage";
CM_ SG_ 2433155120 DC_voltage_min_17 "Minimum allowable dc voltage";
CM_ SG_ 2433155120 DC_voltage_max_17 "Maximum allowable dc voltage";
CM_ SG_ 2433155121 Phase_current_min_17 "Minimum allowable output current";
CM_ SG_ 2433155121 Phase_current_max_17 "Maximum allowable output current";
CM_ SG_ 2433155148 Group_ID_17 "Desired group ID for the device";
CM_ SG_ 2433187855 Group_ID_17 "Group ID of the device";
CM_ SG_ 2433155169 Factory_mode_17 "Customers MUST NOT USE this bit. If set to 1, module will enter in factory mode. ";
CM_ SG_ 2433155169 Silent_CAN_mode_17 "Customers MUST NOT USE this bit. If set to 1, module will enter in factory mode. ";
CM_ SG_ 2433155146 start_17 "Start automatic calibration. Multiplexer index must be 0!";
CM_ SG_ 2433155147 point_17 "Calibration point index.";
CM_ SG_ 2433155142 CRC_17 "Checksum of bytes 0 to 3, CRC-CCITT, corresponding to qChecksum (www.qt.io)";
CM_ SG_ 2433155143 CRC_17 "Checksum of bytes 0 to 3, CRC-CCITT, corresponding to qChecksum (www.qt.io)";
CM_ SG_ 2433187926 Current_U_High_17 "This flag is set if a hight current on U tripped the internal interlock";
CM_ SG_ 2433187926 Current_U_Low_17 "This flag is set if a low current on U tripped the internal interlock";
CM_ SG_ 2433187926 Current_V_High_17 "This flag is set if a hight current on V tripped the internal interlock";
CM_ SG_ 2433187926 Current_V_Low_17 "This flag is set if a low current on V tripped the internal interlock";
CM_ SG_ 2433187926 Current_W_High_17 "This flag is set if a hight current on W tripped the internal interlock";
CM_ SG_ 2433187926 Current_W_Low_17 "This flag is set if a low current on W tripped the internal interlock";
CM_ SG_ 2433187926 Voltage_DC_17 "This flag is set if a voltage on DC tripped the internal interlock";
CM_ SG_ 2433187926 Reboot_17 "This flag is set if a reboot tripped the internal interlock";
CM_ SG_ 2433187926 Unknown_17 "This flag the reason for the internal interlock is unknown";

BA_DEF_ BO_ "SystemMessageLongSymbol" STRING;

BA_ "SystemMessageLongSymbol" BO_ 2433155137 "AFE_Reactive_Current_Setpoint_Control_17";
BA_ "SystemMessageLongSymbol" BO_ 2433155144 "AFE_Frequency_Setpoint_Control_17";
BA_ "SystemMessageLongSymbol" BO_ 2433155184 "AFE_Rectifier_Setpoint_Control_17";
BA_ "SystemMessageLongSymbol" BO_ 2433155142 "_AFE_Calibration_Offset_Update_17";

VAL_ 2433187840 Device_type_17 7 "AFE";
VAL_ 2433187846 Protection_trip_internal_17 1 "fault";
VAL_ 2433187846 Protection_trip_external_17 1 "fault";
VAL_ 2433187846 Phase_U_overcurrent_17 1 "fault";
VAL_ 2433187846 Phase_U_overvoltage_17 1 "fault";
VAL_ 2433187846 Phase_U_undervoltage_17 1 "fault";
VAL_ 2433187846 Phase_V_overvoltage_17 1 "fault";
VAL_ 2433187846 Phase_V_undervoltage_17 1 "fault";
VAL_ 2433187846 Phase_V_overcurrent_17 1 "fault";
VAL_ 2433187846 Phase_W_overvoltage_17 1 "fault";
VAL_ 2433187846 Phase_W_undervoltage_17 1 "fault";
VAL_ 2433187846 Phase_W_overcurrent_17 1 "fault";
VAL_ 2433187846 DC_undervoltage_17 1 "fault";
VAL_ 2433187846 DC_overvoltage_17 1 "fault";
VAL_ 2433187846 MOSFET_overtemperature_17 1 "fault";
VAL_ 2433187846 Inductor_overtemperature_17 1 "fault";
VAL_ 2433187846 Keep_Alive_not_served_17 1 "fault";
VAL_ 2433187846 PLL_not_locked_17 1 "fault";
VAL_ 2433187846 NFO_17 1 "fault";
VAL_ 2433187846 Measurement_system_failure_17 1 "fault";
VAL_ 2433187846 EEPROM_failure_17 1 "fault";
VAL_ 2433187846 System_17 1 "fault";
VAL_ 2433187926 Current_U_High_17 1 "fault";
VAL_ 2433187926 Current_U_Low_17 1 "fault";
VAL_ 2433187926 Current_V_High_17 1 "fault";
VAL_ 2433187926 Current_V_Low_17 1 "fault";
VAL_ 2433187926 Current_W_High_17 1 "fault";
VAL_ 2433187926 Current_W_Low_17 1 "fault";
VAL_ 2433187926 Voltage_DC_17 1 "fault";
VAL_ 2433187926 Reboot_17 1 "fault";
VAL_ 2433187926 Unknown_17 1 "fault";
SIG_VALTYPE_ 2433187921 Current_U_17 : 1;
SIG_VALTYPE_ 2433187921 Current_V_17 : 1;
SIG_VALTYPE_ 2433187921 Current_W_17 : 1;
SIG_VALTYPE_ 2433187921 Voltage_U_17 : 1;
SIG_VALTYPE_ 2433187921 Voltage_V_17 : 1;
SIG_VALTYPE_ 2433187921 Voltage_W_17 : 1;
SIG_VALTYPE_ 2433187921 Voltage_DC_17 : 1;
SIG_VALTYPE_ 2433187922 Current_U_17 : 1;
SIG_VALTYPE_ 2433187922 Current_V_17 : 1;
SIG_VALTYPE_ 2433187922 Current_W_17 : 1;
SIG_VALTYPE_ 2433187922 Voltage_U_17 : 1;
SIG_VALTYPE_ 2433187922 Voltage_V_17 : 1;
SIG_VALTYPE_ 2433187922 Voltage_W_17 : 1;
SIG_VALTYPE_ 2433187922 Voltage_DC_17 : 1;
